AUTOSAR XML (schema 00051)
package /adcm/AdaptiveApplicationSwComponentTypes
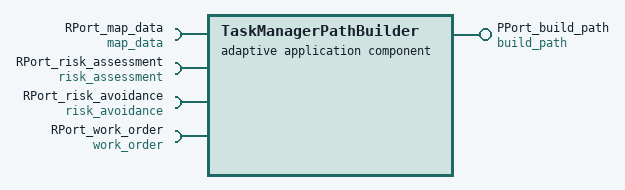
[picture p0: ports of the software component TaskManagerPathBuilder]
  adaptive application sw component type TaskManagerPathBuilder
    provide port PPort_build_path: provided-interface=build_path
    4 x require port:
      RPort_map_data: required-interface=map_data
      RPort_risk_assessment: required-interface=risk_assessment
      RPort_risk_avoidance: required-interface=risk_avoidance
      RPort_work_order: required-interface=work_order
package /adcm/Executables
  executable TaskManagerPathBuilder: category=APPLICATION_LEVEL, minimum-timer-granularity=1000
    root sw component prototype TaskManagerPathBuilder: application-type=TaskManagerPathBuilder
